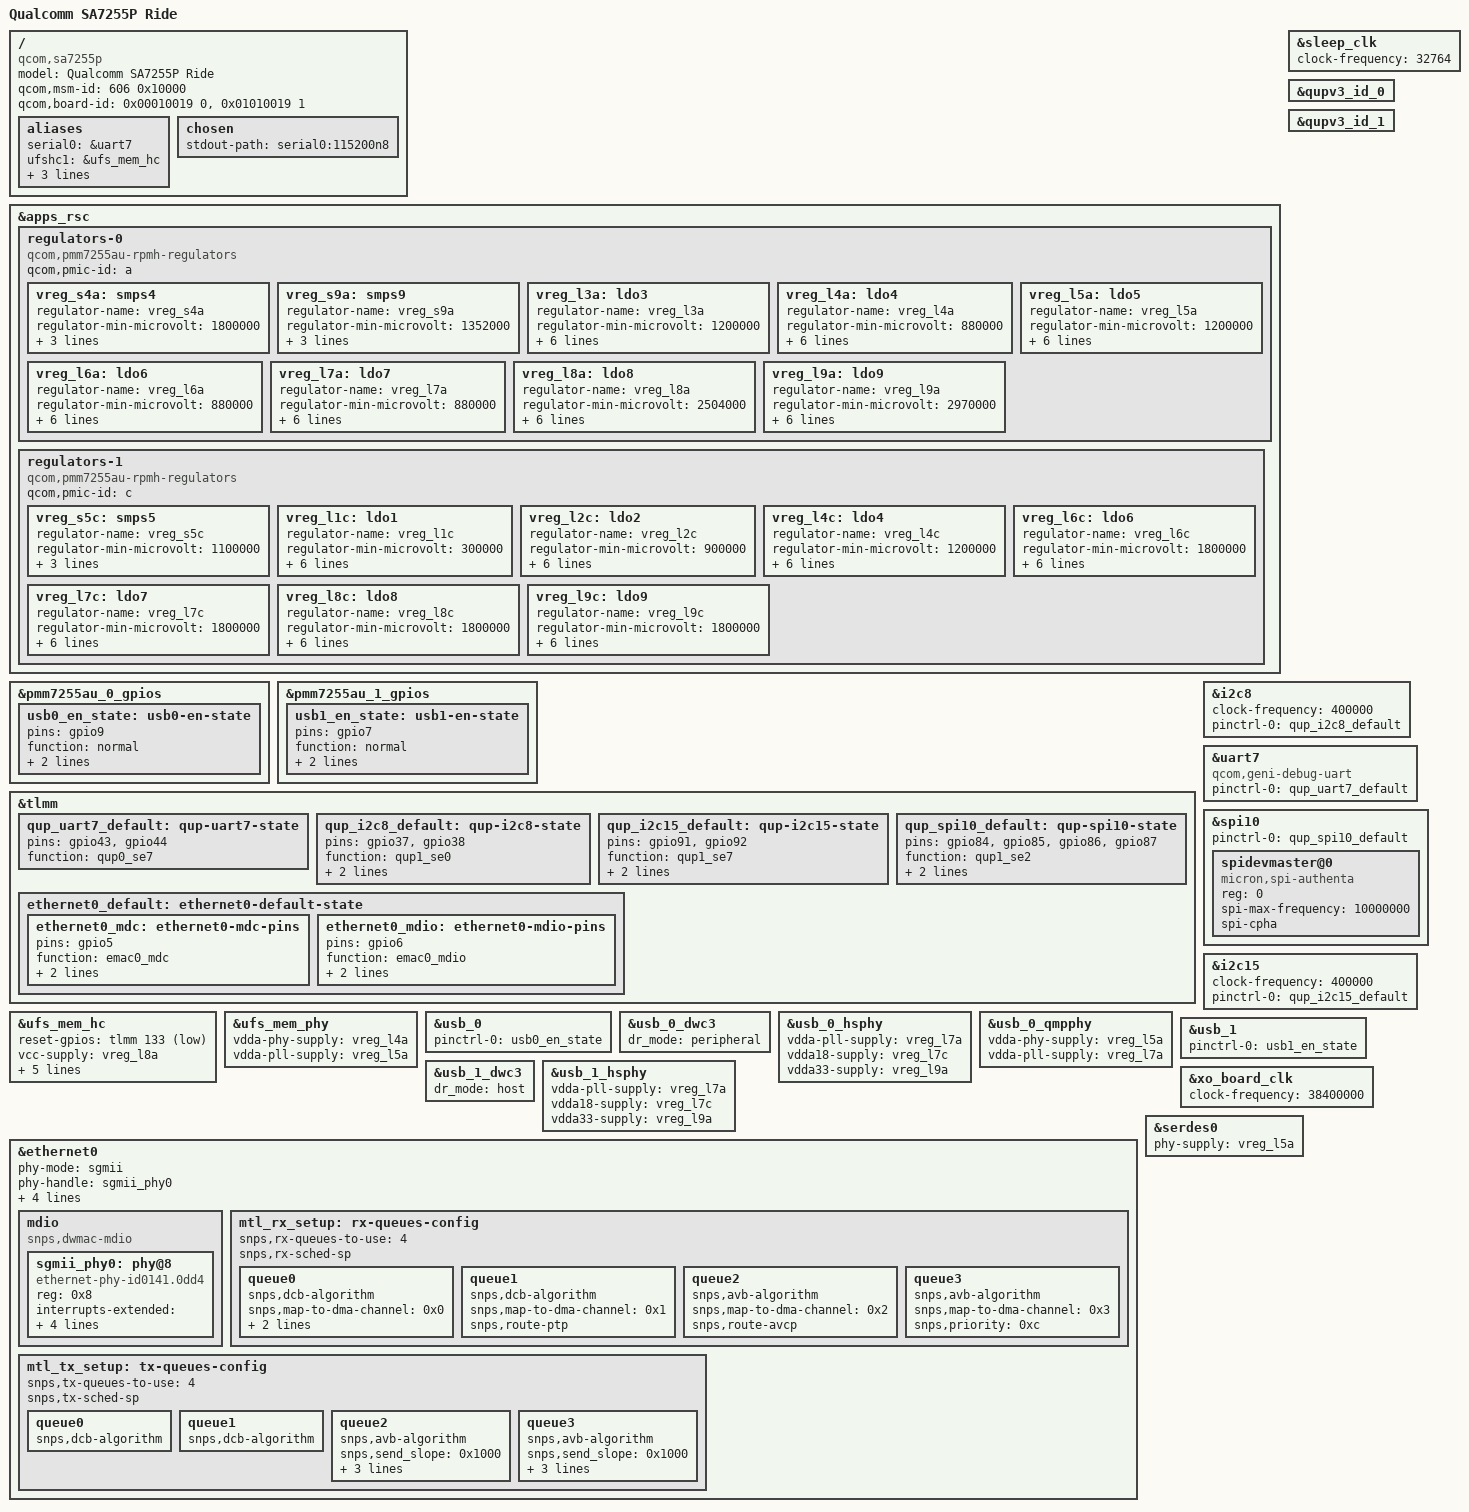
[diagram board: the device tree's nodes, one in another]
// SPDX-License-Identifier: BSD-3-Clause
/*
 * Copyright (c) 2024 Qualcomm Innovation Center, Inc. All rights reserved.
 */

/dts-v1/;

#include <dt-bindings/gpio/gpio.h>
#include <dt-bindings/regulator/qcom,rpmh-regulator.h>

#include "sa7255p.dtsi"
#include "sa7255p-vfio.dtsi"
#include "sa7255p-vms.dtsi"
#include "sa7255p-pmics.dtsi"

/ {
	model = "Qualcomm SA7255P Ride";
	compatible = "qcom,sa7255p";
	qcom,msm-id = <606 0x10000>;
	qcom,board-id = <0x00010019 0>, <0x01010019 1>;

	aliases {
		serial0 = &uart7;
		ufshc1 = &ufs_mem_hc;
		i2c8 = &i2c8;
		i2c15 = &i2c15;
		spi10 = &spi10;
	};

	chosen {
		stdout-path = "serial0:115200n8";
	};
};

&apps_rsc {
	regulators-0 {
		compatible = "qcom,pmm7255au-rpmh-regulators";
		qcom,pmic-id = "a";

		vreg_s4a: smps4 {
			regulator-name = "vreg_s4a";
			regulator-min-microvolt = <1800000>;
			regulator-max-microvolt = <1800000>;
			regulator-initial-mode = <RPMH_REGULATOR_MODE_HPM>;
		};

		vreg_s9a: smps9 {
			regulator-name = "vreg_s9a";
			regulator-min-microvolt = <1352000>;
			regulator-max-microvolt = <1352000>;
			regulator-initial-mode = <RPMH_REGULATOR_MODE_HPM>;
		};

		vreg_l3a: ldo3 {
			regulator-name = "vreg_l3a";
			regulator-min-microvolt = <1200000>;
			regulator-max-microvolt = <1200000>;
			regulator-initial-mode = <RPMH_REGULATOR_MODE_HPM>;
			regulator-allow-set-load;
			regulator-allowed-modes = <RPMH_REGULATOR_MODE_LPM
						   RPMH_REGULATOR_MODE_HPM>;
		};

		vreg_l4a: ldo4 {
			regulator-name = "vreg_l4a";
			regulator-min-microvolt = <880000>;
			regulator-max-microvolt = <912000>;
			regulator-initial-mode = <RPMH_REGULATOR_MODE_HPM>;
			regulator-allow-set-load;
			regulator-allowed-modes = <RPMH_REGULATOR_MODE_LPM
						   RPMH_REGULATOR_MODE_HPM>;
		};

		vreg_l5a: ldo5 {
			regulator-name = "vreg_l5a";
			regulator-min-microvolt = <1200000>;
			regulator-max-microvolt = <1200000>;
			regulator-initial-mode = <RPMH_REGULATOR_MODE_HPM>;
			regulator-allow-set-load;
			regulator-allowed-modes = <RPMH_REGULATOR_MODE_LPM
						   RPMH_REGULATOR_MODE_HPM>;
		};

		vreg_l6a: ldo6 {
			regulator-name = "vreg_l6a";
			regulator-min-microvolt = <880000>;
			regulator-max-microvolt = <912000>;
			regulator-initial-mode = <RPMH_REGULATOR_MODE_HPM>;
			regulator-allow-set-load;
			regulator-allowed-modes = <RPMH_REGULATOR_MODE_LPM
						   RPMH_REGULATOR_MODE_HPM>;
		};

		vreg_l7a: ldo7 {
			regulator-name = "vreg_l7a";
			regulator-min-microvolt = <880000>;
			regulator-max-microvolt = <912000>;
			regulator-initial-mode = <RPMH_REGULATOR_MODE_HPM>;
			regulator-allow-set-load;
			regulator-allowed-modes = <RPMH_REGULATOR_MODE_LPM
						   RPMH_REGULATOR_MODE_HPM>;
		};

		vreg_l8a: ldo8 {
			regulator-name = "vreg_l8a";
			regulator-min-microvolt = <2504000>;
			regulator-max-microvolt = <2960000>;
			regulator-initial-mode = <RPMH_REGULATOR_MODE_HPM>;
			regulator-allow-set-load;
			regulator-allowed-modes = <RPMH_REGULATOR_MODE_LPM
						   RPMH_REGULATOR_MODE_HPM>;
		};

		vreg_l9a: ldo9 {
			regulator-name = "vreg_l9a";
			regulator-min-microvolt = <2970000>;
			regulator-max-microvolt = <3072000>;
			regulator-initial-mode = <RPMH_REGULATOR_MODE_HPM>;
			regulator-allow-set-load;
			regulator-allowed-modes = <RPMH_REGULATOR_MODE_LPM
						   RPMH_REGULATOR_MODE_HPM>;
		};
	};

	regulators-1 {
		compatible = "qcom,pmm7255au-rpmh-regulators";
		qcom,pmic-id = "c";

		vreg_s5c: smps5 {
			regulator-name = "vreg_s5c";
			regulator-min-microvolt = <1100000>;
			regulator-max-microvolt = <1100000>;
			regulator-initial-mode = <RPMH_REGULATOR_MODE_HPM>;
		};

		vreg_l1c: ldo1 {
			regulator-name = "vreg_l1c";
			regulator-min-microvolt = <300000>;
			regulator-max-microvolt = <500000>;
			regulator-initial-mode = <RPMH_REGULATOR_MODE_HPM>;
			regulator-allow-set-load;
			regulator-allowed-modes = <RPMH_REGULATOR_MODE_LPM
						   RPMH_REGULATOR_MODE_HPM>;
		};

		vreg_l2c: ldo2 {
			regulator-name = "vreg_l2c";
			regulator-min-microvolt = <900000>;
			regulator-max-microvolt = <904000>;
			regulator-initial-mode = <RPMH_REGULATOR_MODE_HPM>;
			regulator-allow-set-load;
			regulator-allowed-modes = <RPMH_REGULATOR_MODE_LPM
						   RPMH_REGULATOR_MODE_HPM>;
		};

		vreg_l4c: ldo4 {
			regulator-name = "vreg_l4c";
			regulator-min-microvolt = <1200000>;
			regulator-max-microvolt = <1200000>;
			regulator-initial-mode = <RPMH_REGULATOR_MODE_HPM>;
			regulator-allow-set-load;
			regulator-allowed-modes = <RPMH_REGULATOR_MODE_LPM
						   RPMH_REGULATOR_MODE_HPM>;
		};

		vreg_l6c: ldo6 {
			regulator-name = "vreg_l6c";
			regulator-min-microvolt = <1800000>;
			regulator-max-microvolt = <1800000>;
			regulator-initial-mode = <RPMH_REGULATOR_MODE_HPM>;
			regulator-allow-set-load;
			regulator-allowed-modes = <RPMH_REGULATOR_MODE_LPM
						   RPMH_REGULATOR_MODE_HPM>;
		};

		vreg_l7c: ldo7 {
			regulator-name = "vreg_l7c";
			regulator-min-microvolt = <1800000>;
			regulator-max-microvolt = <1800000>;
			regulator-initial-mode = <RPMH_REGULATOR_MODE_HPM>;
			regulator-allow-set-load;
			regulator-allowed-modes = <RPMH_REGULATOR_MODE_LPM
						   RPMH_REGULATOR_MODE_HPM>;
		};

		vreg_l8c: ldo8 {
			regulator-name = "vreg_l8c";
			regulator-min-microvolt = <1800000>;
			regulator-max-microvolt = <1800000>;
			regulator-initial-mode = <RPMH_REGULATOR_MODE_HPM>;
			regulator-allow-set-load;
			regulator-allowed-modes = <RPMH_REGULATOR_MODE_LPM
						   RPMH_REGULATOR_MODE_HPM>;
		};

		vreg_l9c: ldo9 {
			regulator-name = "vreg_l9c";
			regulator-min-microvolt = <1800000>;
			regulator-max-microvolt = <1800000>;
			regulator-initial-mode = <RPMH_REGULATOR_MODE_HPM>;
			regulator-allow-set-load;
			regulator-allowed-modes = <RPMH_REGULATOR_MODE_LPM
						   RPMH_REGULATOR_MODE_HPM>;
		};
	};
};

&pmm7255au_0_gpios {
	usb0_en_state: usb0-en-state {
		pins = "gpio9";
		function = "normal";
		output-high;
		power-source = <0>;
	};
};

&pmm7255au_1_gpios {
	usb1_en_state: usb1-en-state {
		pins = "gpio7";
		function = "normal";
		output-high;
		power-source = <0>;
	};
};

&sleep_clk {
	clock-frequency = <32764>;
};

&qupv3_id_0 {
	status = "okay";
};

&qupv3_id_1 {
	status = "okay";
};

&tlmm {
	qup_uart7_default: qup-uart7-state {
		pins = "gpio43", "gpio44";
		function = "qup0_se7";
	};

	qup_i2c8_default: qup-i2c8-state {
		pins = "gpio37", "gpio38";
		function = "qup1_se0";
		drive-strength = <2>;
		bias-pull-up;
	};

	qup_i2c15_default: qup-i2c15-state {
		pins = "gpio91", "gpio92";
		function = "qup1_se7";
		drive-strength = <2>;
		bias-pull-up;
	};

	qup_spi10_default: qup-spi10-state {
		pins = "gpio84", "gpio85", "gpio86", "gpio87";
		function = "qup1_se2";
		drive-strength = <6>;
		bias-disable;
	};
};

&i2c8 {
	clock-frequency = <400000>;
	pinctrl-0 = <&qup_i2c8_default>;
	pinctrl-names = "default";
	status = "okay";
};

&uart7 {
	compatible = "qcom,geni-debug-uart";
	pinctrl-0 = <&qup_uart7_default>;
	pinctrl-names = "default";
	status = "okay";
};

&spi10 {
	pinctrl-0 = <&qup_spi10_default>;
	pinctrl-names = "default";
	status = "okay";

	spidevmaster@0 {
		/* FIXME: Replace below compatible once we have proper dt-bindings
		 * for the NXPs Mercury Audio DSP SAF4000EL/101(ES).
		 */
		compatible = "micron,spi-authenta";
		reg = <0>;
		spi-max-frequency = <10000000>;
		spi-cpha;
		status = "okay";
	};
};

&i2c15 {
	clock-frequency = <400000>;
	pinctrl-0 = <&qup_i2c15_default>;
	pinctrl-names = "default";
	status = "okay";
};

&ufs_mem_hc {
	reset-gpios = <&tlmm 133 GPIO_ACTIVE_LOW>;
	vcc-supply = <&vreg_l8a>;
	vcc-max-microamp = <1100000>;
	vccq-supply = <&vreg_l4c>;
	vccq-max-microamp = <1200000>;
	vccq2-supply = <&vreg_s4a>;
	vccq2-max-microamp = <800000>;
	status = "okay";
};

&ufs_mem_phy {
	vdda-phy-supply = <&vreg_l4a>;
	vdda-pll-supply = <&vreg_l5a>;

	status = "okay";
};

&usb_0 {
	pinctrl-names = "default";
	pinctrl-0 = <&usb0_en_state>;

	status = "okay";
};

&usb_0_dwc3 {
	dr_mode = "peripheral";
};

&usb_0_hsphy {
	vdda-pll-supply = <&vreg_l7a>;
	vdda18-supply = <&vreg_l7c>;
	vdda33-supply = <&vreg_l9a>;

	status = "okay";
};

&usb_0_qmpphy {
	vdda-phy-supply = <&vreg_l5a>;
	vdda-pll-supply = <&vreg_l7a>;

	status = "okay";
};

&usb_1 {
	pinctrl-names = "default";
	pinctrl-0 = <&usb1_en_state>;

	status = "okay";
};

&usb_1_dwc3 {
	dr_mode = "host";
};

&usb_1_hsphy {
	vdda-pll-supply = <&vreg_l7a>;
	vdda18-supply = <&vreg_l7c>;
	vdda33-supply = <&vreg_l9a>;

	status = "okay";
};

&xo_board_clk {
	clock-frequency = <38400000>;
};

&ethernet0 {
	phy-mode = "sgmii";
	phy-handle = <&sgmii_phy0>;

	pinctrl-0 = <&ethernet0_default>;
	pinctrl-names = "default";

	snps,mtl-rx-config = <&mtl_rx_setup>;
	snps,mtl-tx-config = <&mtl_tx_setup>;
	snps,ps-speed = <1000>;

	status = "okay";

	mdio {
		compatible = "snps,dwmac-mdio";
		#address-cells = <1>;
		#size-cells = <0>;

		sgmii_phy0: phy@8 {
			compatible = "ethernet-phy-id0141.0dd4";
			reg = <0x8>;
			device_type = "ethernet-phy";
			interrupts-extended = <&tlmm 4 IRQ_TYPE_EDGE_FALLING>;
			reset-gpios = <&tlmm 31 GPIO_ACTIVE_LOW>;
			reset-assert-us = <11000>;
			reset-deassert-us = <70000>;
		};
	};

	mtl_rx_setup: rx-queues-config {
		snps,rx-queues-to-use = <4>;
		snps,rx-sched-sp;

		queue0 {
			snps,dcb-algorithm;
			snps,map-to-dma-channel = <0x0>;
			snps,route-up;
			snps,priority = <0x1>;
		};

		queue1 {
			snps,dcb-algorithm;
			snps,map-to-dma-channel = <0x1>;
			snps,route-ptp;
		};

		queue2 {
			snps,avb-algorithm;
			snps,map-to-dma-channel = <0x2>;
			snps,route-avcp;
		};

		queue3 {
			snps,avb-algorithm;
			snps,map-to-dma-channel = <0x3>;
			snps,priority = <0xc>;
		};
	};

	mtl_tx_setup: tx-queues-config {
		snps,tx-queues-to-use = <4>;
		snps,tx-sched-sp;

		queue0 {
			snps,dcb-algorithm;
		};

		queue1 {
			snps,dcb-algorithm;
		};

		queue2 {
			snps,avb-algorithm;
			snps,send_slope = <0x1000>;
			snps,idle_slope = <0x1000>;
			snps,high_credit = <0x3e800>;
			snps,low_credit = <0xffc18000>;
		};

		queue3 {
			snps,avb-algorithm;
			snps,send_slope = <0x1000>;
			snps,idle_slope = <0x1000>;
			snps,high_credit = <0x3e800>;
			snps,low_credit = <0xffc18000>;
		};
	};
};

&serdes0 {
	phy-supply = <&vreg_l5a>;
	status = "okay";
};

&tlmm {
	ethernet0_default: ethernet0-default-state {
		ethernet0_mdc: ethernet0-mdc-pins {
			pins = "gpio5";
			function = "emac0_mdc";
			drive-strength = <16>;
			bias-pull-up;
		};

		ethernet0_mdio: ethernet0-mdio-pins {
			pins = "gpio6";
			function = "emac0_mdio";
			drive-strength = <16>;
			bias-pull-up;
		};
	};
};
